# PIC32MK0512GPD100 device description
Architecture: MIPS; Family: PIC32MK; Series: PIC32MK
Registers are 32-bit, read-write, no defined reset value unless marked. A register's access mark holds for its fields unless they carry their own. Offsets are from the block's base; [hi:lo] are bit positions; {n}, {i} and the like mark numbered series; 'fields as' and 'values as' point back to an identical list; <NAME> marks a mode.

## CMP
Instances: CMP 0x1f82c000 in periph_pb2_std
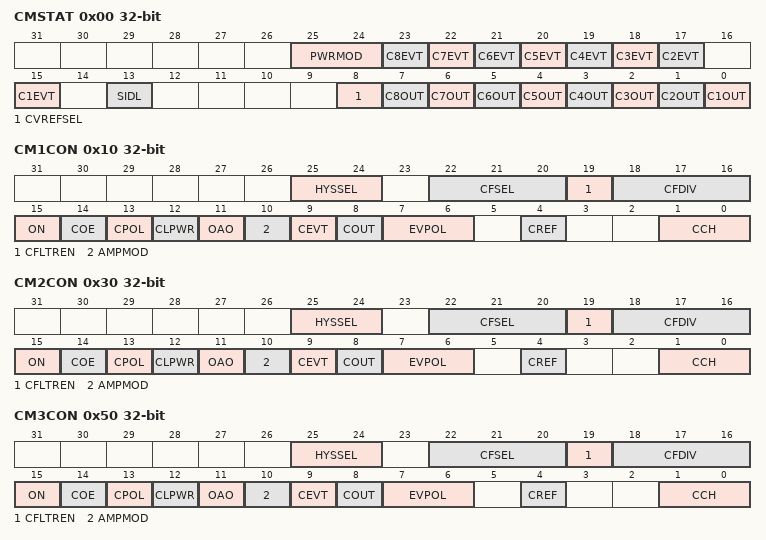
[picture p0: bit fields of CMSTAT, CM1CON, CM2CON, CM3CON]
0x00 CMSTAT — Op amp/Comparator Status Register
  [25:24] PWRMOD
  [n+15] C{n}EVT (n=2..8)
  [15] C1EVT
  [13] SIDL — Stop in Idle Mode bit
    1=Discontinue operation of all Op amp/Comparators when device enters Idle mode; 0=Continue module operation in Idle mode
  [8] CVREFSEL
  [7] C8OUT
  [6] C7OUT
  [5] C6OUT
  [n-1] C{n}OUT (n=1..5) — Op amp/Comparator {n} Output Status bit
    1=(When CPOL is 0) Vin+ > Vth+ / (When CPOL is 1) VIN+ Vth+ / (When CPOL is 1) VIN+ < VTH-; 0=(When CPOL is 0) VIN+ VTH+
0x10 CM1CON — Op amp/Comparator 'x' Control Register ('x' = 1-5)
  [25:24] HYSSEL
  [22:20] CFSEL — Comparator Output Filter Clock Source Select bits
    {v}=PBCLK2/Timer{v-2} Period Value (PR{v-2}) (v=4..7); 3=REFCLK3 Clock; 2=PWM Secondary Special Event; 1=PPBCLK2 Clock; 0=SYSCLK Clock
  [19] CFLTREN — Comparator Output Digital Filter Enable bit
    1=Digital Filters enabled; 0=Digital Filters disabled
  [18:16] CFDIV — Comparator Output Filter Clock Divide Select bits
    7=1:128 Clock Divide; 6=1:64 Clock Divide; 5=1:32 Clock Divide; 4=1:16 Clock Divide; 3=1:8 Clock Divide; 2=1:4 Clock Divide; 1=1:2 Clock Divide; 0=1:1 Clock Divide
  [15] ON — Comparator Enable bit
    1=Comparator is enabled; 0=Comparator is disabled
  [14] COE — Comparator Output Enable bit
    1=Comparator output is present on the CxOUT pin; 0=Comparator output is internal only
  [13] CPOL — Comparator Output Polarity Select bit
    1=Comparator output is inverted; 0=Comparator output is not inverted
  [12] CLPWR
  [11] OAO — Op amp Output Enable bit
    1=Op amp output is present on the OAxOUT pin; 0=Op amp output is not present on the OAxOUT pin
  [10] AMPMOD — Op amp Mode Enable bit
    1=Amplifier/Comparator operating in Dual mode (both Op amps and Comparators are enabled); 0=Amplifier/Comparator operating in Comparator-only mode
  [9] CEVT
  [8] COUT — Comparator Output bit
    1=(When CPOL is 0)VIN+ > VTH+ / (When CPOL is 1) VIN+ VTH+ / (When CPOL is 1) VIN+ < VTH-; 0=(When CPOL is 0)VIN+ VTH+
  [7:6] EVPOL — Trigger/Event Polarity Select bits
    3=Trigger/Event generated on any change of the comparator output; 2=(If CPOL is 0) High-to-low transition of the comparator output / (If CPOL is 1) Low-to-high transition of the comparator output; 1=(If CPOL is 0) Low-to-high transition of the comparator output / (If CPOL is 1) High-to-low transition of the comparator output; 0=Trigger/Event generation is disabled
  [4] CREF — Op amp/Comparator Reference Select bit
    1=VIN+ input connects to internal CDAC3 output voltage; 0=VIN+ input connects to CxIN1+ pin
  [1:0] CCH — Comparator Channel Select bits
    {v}=CxIN{v+1}- (v=0..3)
0x30 CM2CON — Op amp/Comparator 'x' Control Register ('x' = 1-5)
  fields as CM1CON
0x50 CM3CON — Op amp/Comparator 'x' Control Register ('x' = 1-5)
  fields as CM1CON
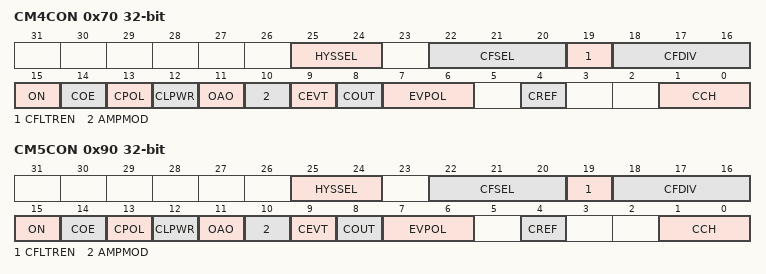
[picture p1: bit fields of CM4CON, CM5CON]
0x70 CM4CON — Op amp/Comparator 'x' Control Register ('x' = 1-5)
  fields as CM1CON
0x90 CM5CON — Op amp/Comparator 'x' Control Register ('x' = 1-5)
  fields as CM1CON

## CTMU
Instances: CTMU 0x1f82d000 in periph_pb2_std
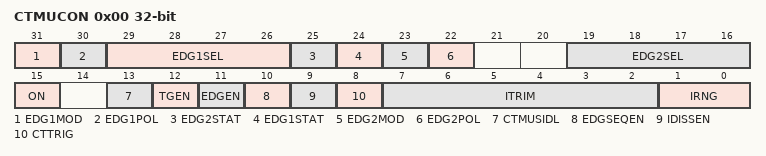
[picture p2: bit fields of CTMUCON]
0x00 CTMUCON — CTMU Control Register
  [31] EDG1MOD — Edge1 Edge Sampling Select bit
    1=Input is edge-sensitive; 0=Input is level-sensitive
  [30] EDG1POL — Edge 1 Polarity Select bit
    1=Edge1 programmed for a positive edge response; 0=Edge1 programmed for a negative edge response
  [29:26] EDG1SEL — Edge 1 Source Select bits
    14=C2OUT pin is selected; 13=C1OUT pin is selected; {v}=IC{v-6} Capture Event is selected (v=7..12); 6=OC4 Capture Event is selected; 5=OC3 Capture Event is selected; 4=OC2 Capture Event is selected; 3=CTED1 pin is selected; 2=CTED2 pin is selected; 1=OC1 Compare Event is selected; 0=Timer1 Event is selected
  [25] EDG2STAT — Edge2 Status bit
    1=Edge2 has occurred; 0=Edge2 has not occurred
  [24] EDG1STAT — Edge1 Status bit
    1=Edge1 has occurred; 0=Edge1 has not occurred
  [23] EDG2MOD — Edge2 Edge Sampling Select bit
    1=Input is edge-sensitive; 0=Input is level-sensitive
  [22] EDG2POL — Edge 2 Polarity Select bit
    1=Edge2 programmed for a positive edge response; 0=Edge2 programmed for a negative edge response
  [19:16] EDG2SEL — Edge 2 Source Select bits
    56=C2OUT pin is selected; 52=C1OUT pin is selected; 48=PBCLK3; 44=IC5 Capture Event is selected; 40=IC4 Capture Event is selected; 36=IC3 Capture Event is selected; 32=IC2 Capture Event is selected; 28=IC1 Capture Event is selected; 24=OC4 Capture Event is selected; 20=OC3 Capture Event is selected; 16=OC2 Capture Event is selected; 12=CTED1 pin is selected; 8=CTED2 pin is selected; 4=OC1 Compare Event is selected; 0=Timer1 Event is selected
  [15] ON — ON Enable bit
    1=Module is enabled; 0=OFF (Module is disabled)
  [13] CTMUSIDL — Stop-in-Idle Mode bit
    1=Discontinue module operation when device enters Idle mode; 0=Continue module operation in Idle mode
  [12] TGEN — Time Generation Enable bit
    1=Enables edge delay generation; 0=Disables edge delay generation
  [11] EDGEN — Edge Enable bit
    1=Edges are not blocked; 0=Edges are blocked
  [10] EDGSEQEN — Edge Sequence Enable bit
    1=Edge1 must occur before Edge2 can occur; 0=No edge sequence is needed
  [9] IDISSEN — Analog Current Source Control bit
    1=Analog current source output is grounded; 0=Analog current source output is not grounded
  [8] CTTRIG — Trigger Control bit
    1=Trigger output is enabled; 0=Trigger output is disabled
  [7:2] ITRIM — Current Source Trim bits
    31=Maximum positive change from nominal current; 1=Minimum positive change from nominal current; 0=Nominal current output specified by IRNG; 63=Minimum negative change from nominal current; 33=Maximum negative change from nominal current
  [1:0] IRNG — Current Range Select bits
    3=100 times base current; 2=10 times base current; 1=Base current level; 0=1000 times base current

## Notices in the file
Copyright (c) 2017 Microchip Technology Inc.
SPDX-License-Identifier: Apache-2.0
Licensed under the Apache License, Version 2.0 (the "License");
you may not use this file except in compliance with the License.
You may obtain a copy of the License at
http://www.apache.org/licenses/LICENSE-2.0
Unless required by applicable law or agreed to in writing, software
distributed under the License is distributed on an "AS IS" BASIS,
WITHOUT WARRANTIES OR CONDITIONS OF ANY KIND, either express or implied.
See the License for the specific language governing permissions and
limitations under the License.
